# WB32F10x register map
File version: 1.2
CPU: CM3 r2p0, little endian, MPU, no FPU, 4 interrupt priority bits
Registers are 32-bit, read-write, reset 0x0 unless marked. A register's access mark holds for its fields unless they carry their own. Offsets are from the block's base; [hi:lo] are bit positions; {n}, {i} and the like mark numbered series; 'fields as' and 'values as' point back to an identical list.

## TIM1 — Timer 1
Base 0x40001C00
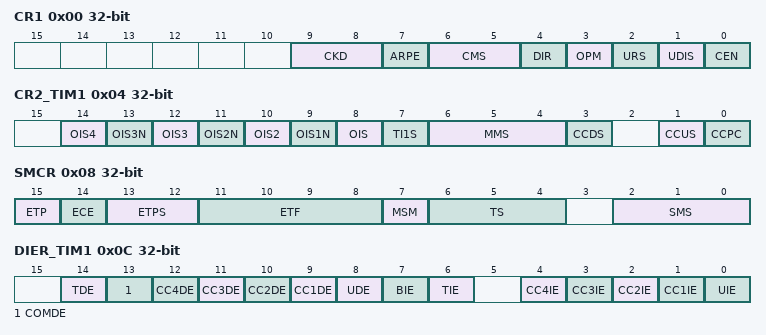
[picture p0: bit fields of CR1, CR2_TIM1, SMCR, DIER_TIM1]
0x00 CR1 — Timer control register 1
  [9:8] CKD — Clock division
  [7] ARPE — Auto-reload preload enable
  [6:5] CMS — Center-aligned mode selection
  [4] DIR — Counter Direction
  [3] OPM — One pulse mode
  [2] URS — Update request source
  [1] UDIS — Update disable
  [0] CEN — Counter enable
0x04 CR2_TIM1 — Timer 1 control register 2
  [14] OIS4 — Out idle state 4
  [13] OIS3N — Negative out idle state 3
  [12] OIS3 — Out idle state 1
  [11] OIS2N — Negative out idle state 2
  [10] OIS2 — Out idle state 2
  [9] OIS1N — Negative out idle state 1
  [8] OIS — Out idle state 1
  [7] TI1S — TI1 selection
  [6:4] MMS — Master mode selection
    0=TIM_TRGOSource_Reset (Timer reset event selected as trigger output); 1=TIM_TRGOSource_Enable (Timer enable event selected as trigger output); 2=TIM_TRGOSource_Update (Timer update event selected as trigger output); 3=TIM_TRGOSource_OC1 (Timer capture/compare event selected as trigger output); {v}=TIM_TRGOSource_OC{v-3}Ref (Timer channel {v-3} output compare event selected as trigger output) (v=4..7)
  [3] CCDS — Capture/compare DMA selection
  [1] CCUS — Capture/compare update selection
  [0] CCPC — Capture/compare preload control
0x08 SMCR — Timer slave mode control register
  [15] ETP — External trigger polarity
  [14] ECE — External clock enable
  [13:12] ETPS — External trigger prescaler
  [11:8] ETF — External trigger filter
  [7] MSM — Master/slave mode
  [6:4] TS — Trigger selection
  [2:0] SMS — Slave mode selection
    0=TIM_MasterSlaveMode_Disable (Turn off slave mode); 1=TIM_EncoderMode_TI1 (Encode mode 1); 2=TIM_EncoderMode_TI2 (Encode mode2); 3=TIM_EncoderMode_TI12 (Encode mode 3); 4=TIM_SlaveMode_Reset (Reset mode); 5=TIM_SlaveMode_Gated (Gated mode); 6=TIM_SlaveMode_Trigger (Trigger mode); 7=TIM_SlaveMode_External1 (External clock mode)
0x0C DIER_TIM1 — Timer 1 DMA/interruption enable register
  [14] TDE — Trigger DMA request enable
  [13] COMDE — COM DMA request enable
  [n+8] CC{n}DE (n=1..4) — Capture/Compare {n} DMA request enable
  [8] UDE — Update DMA request enable
  [7] BIE — Break interrupt enable
  [6] TIE — Trigger interrupt enable
  [n] CC{n}IE (n=1..4) — Capture/Compare {n} interrupt enable
  [0] UIE — Update interrupt enable
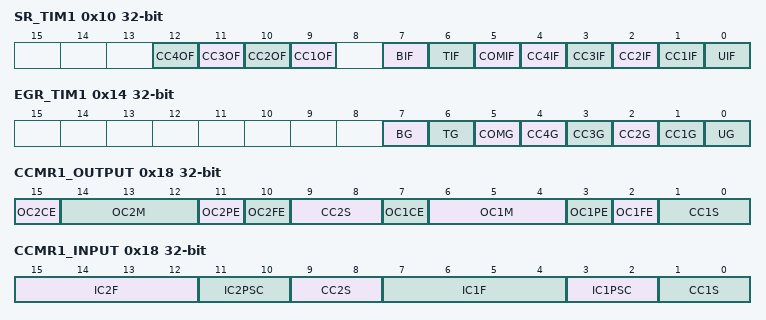
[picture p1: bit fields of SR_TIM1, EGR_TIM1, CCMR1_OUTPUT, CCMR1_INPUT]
0x10 SR_TIM1 — Timer 1 state register
  [n+8] CC{n}OF (n=1..4) — Capture/Compare {n} overcapture flag
  [7] BIF — Break interrupt flag
  [6] TIF — Trigger interrupt flag
  [5] COMIF — COM interrupt flag
  [n] CC{n}IF (n=1..4) — Capture/Compare {n} interrupt flag
  [0] UIF — Update interrupt flag
0x14 EGR_TIM1 wo — Timer 1 event generation register
  [7] BG — Break generation
  [6] TG — Trigger generation
  [5] COMG — Capture/Compare control update generation
  [n] CC{n}G (n=1..4) — Capture/compare {n} generation
  [0] UG — Update generation
0x18 CCMR1_OUTPUT — Capture/compare mode register 1 for output
  [15] OC2CE — Output compare 2 clear enable
  [14:12] OC2M — Output compare 2 enable
  [11] OC2PE — Output compare 2 preload enable
  [10] OC2FE — Output compare 2 fast enable
  [9:8] CC2S — Capture/Compare 2 selection
  [7] OC1CE — Output compare 1 clear enable
  [6:4] OC1M — Output compare 1 enable
  [3] OC1PE — Output compare 1 preload enable
  [2] OC1FE — Output compare 1 fast enable
  [1:0] CC1S — Capture/Compare 1 selection
0x18 CCMR1_INPUT (alternate view of CCMR1_OUTPUT) — Capture/compare mode register 1 for input
  [15:12] IC2F — Input capture 2 filter
  [11:10] IC2PSC — Input capture 2 prescaler
  [9:8] CC2S — Capture/Compare 2 selection
  [7:4] IC1F — Input capture 1 filter
  [3:2] IC1PSC — Input capture 1 prescaler
  [1:0] CC1S — Capture/Compare 1 selection
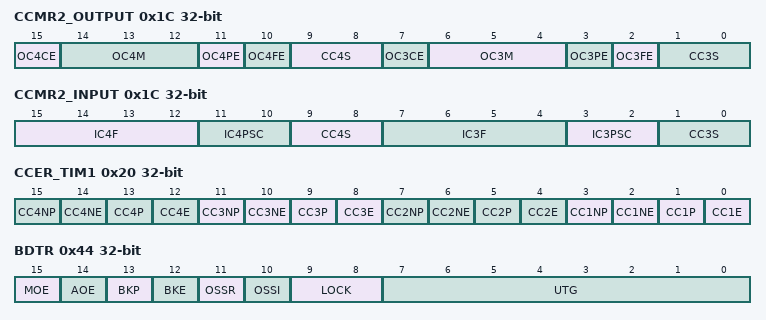
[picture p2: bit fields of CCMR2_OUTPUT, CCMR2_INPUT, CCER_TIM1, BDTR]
0x1C CCMR2_OUTPUT — Capture/compare mode register 2 for output
  [15] OC4CE — Output compare 4 clear enable
  [14:12] OC4M — Output compare 4 enable
  [11] OC4PE — Output compare 4 preload enable
  [10] OC4FE — Output compare 4 fast enable
  [9:8] CC4S — Capture/Compare 4 selection
  [7] OC3CE — Output compare 3 clear enable
  [6:4] OC3M — Output compare 3 enable
  [3] OC3PE — Output compare 3 preload enable
  [2] OC3FE — Output compare 3 fast enable
  [1:0] CC3S — Capture/Compare 3 selection
0x1C CCMR2_INPUT (alternate view of CCMR2_OUTPUT) — Capture/compare mode register 2 for input
  [15:12] IC4F — Input capture 4 filter
  [11:10] IC4PSC — Input capture 4 prescaler
  [9:8] CC4S — Capture/Compare 4 selection
  [7:4] IC3F — Input capture 3 filter
  [3:2] IC3PSC — Input capture 3 prescaler
  [1:0] CC3S — Capture/Compare 3 selection
0x20 CCER_TIM1 — Timer 1 capture/compare enable register
  [4n-1] CC{n}NP (n=1..4) — Capture/Compare {n} negative output polarity
  [4n-2] CC{n}NE (n=1..4) — Capture/Compare {n} negative output enable
  [4n-3] CC{n}P (n=1..4) — Capture/Compare {n} output polarity
  [4n-4] CC{n}E (n=1..4) — Capture/Compare {n} output enable
0x24 CNT — Counter register
  [19:0] CNT — Counter value
0x28 PSC — Prescaler register
  [15:0] PSC — Prescaler value
0x2C ARR — Auto reload register
  [19:0] ARR — Auto reload value
0x30 RCR — Repetition counter register
  [7:0] REP — Repetition counter value
{0x30+4i} CCR{i} (i=1..4) — Capture/compare {i} register
  [19:0] CCR{i} — Capture/Compare {i} value
0x44 BDTR — Break and dead-time register
  [15] MOE — Main output enable
  [14] AOE — Automatic output enable
  [13] BKP — Break polarity
  [12] BKE — Break enable
  [11] OSSR — Off-state selection for Run mode
  [10] OSSI — Off-state selection for idle mode
  [9:8] LOCK — Lock configuration
  [7:0] UTG — Dead-time generator setup

## TIM2 — Timer 2
Base 0x40002000
Same registers: TIM3 0x40002400, TIM4 0x40002800
Registers as TIM1, without CR2_TIM1, DIER_TIM1, SR_TIM1, EGR_TIM1, CCER_TIM1, BDTR; these are added or differ:
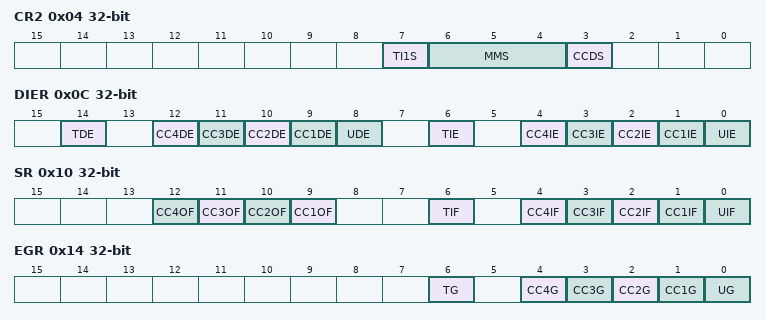
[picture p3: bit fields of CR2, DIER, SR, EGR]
0x04 CR2 (alternate view of CR2_TIM1) — Timer control register 2
  [7] TI1S — TI1 selection
  [6:4] MMS — Master mode selection
    values as TIM1.CR2_TIM1.MMS
  [3] CCDS — Capture/compare DMA selection
0x0C DIER (alternate view of DIER_TIM1) — Timer DMA/interruption enable register
  [14] TDE — Trigger DMA request enable
  [n+8] CC{n}DE (n=1..4) — Capture/Compare {n} DMA request enable
  [8] UDE — Update DMA request enable
  [6] TIE — Trigger interrupt enable
  [n] CC{n}IE (n=1..4) — Capture/Compare {n} interrupt enable
  [0] UIE — Update interrupt enable
0x10 SR (alternate view of SR_TIM1) — Timer state register
  [n+8] CC{n}OF (n=1..4) — Capture/Compare {n} overcapture flag
  [6] TIF — Trigger interrupt flag
  [n] CC{n}IF (n=1..4) — Capture/Compare {n} interrupt flag
  [0] UIF — Update interrupt flag
0x14 EGR wo (alternate view of EGR_TIM1) — Timer event generation register
  [6] TG — Trigger generation
  [n] CC{n}G (n=1..4) — Capture/compare {n} generation
  [0] UG — Update generation
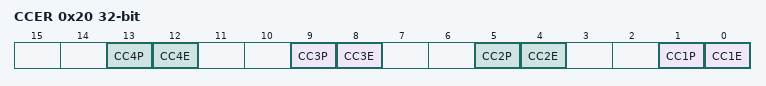
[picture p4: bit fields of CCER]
0x20 CCER (alternate view of CCER_TIM1) — Timer capture/compare enable register
  [4n-3] CC{n}P (n=1..4) — Capture/Compare {n} output polarity
  [4n-4] CC{n}E (n=1..4) — Capture/Compare {n} output enable
